# iom480ae register map
Registers are 32-bit, access not given, no defined reset value unless marked. A register's access mark holds for its fields unless they carry their own. Addresses are absolute; registers are grouped by the start of their names; [hi:lo] are bit positions; 'fields as' and 'values as' point back to an identical list.

## CAN
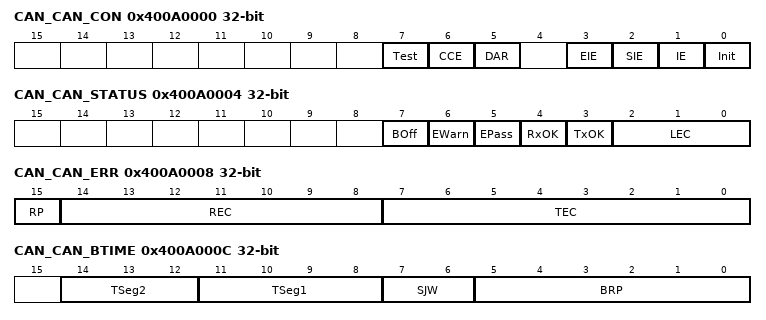
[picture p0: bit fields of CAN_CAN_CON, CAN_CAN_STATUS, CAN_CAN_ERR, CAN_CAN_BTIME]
0x400A0000 CAN_CAN_CON
  [7] Test, [6] CCE, [5] DAR, [3] EIE, [2] SIE, [1] IE, [0] Init
0x400A0004 CAN_CAN_STATUS
  [7] BOff, [6] EWarn, [5] EPass, [4] RxOK, [3] TxOK, [2:0] LEC
0x400A0008 CAN_CAN_ERR
  [15] RP, [14:8] REC, [7:0] TEC
0x400A000C CAN_CAN_BTIME
  [14:12] TSeg2, [11:8] TSeg1, [7:6] SJW, [5:0] BRP
0x400A0010 CAN_CAN_IIDR
  [15:0] IntId
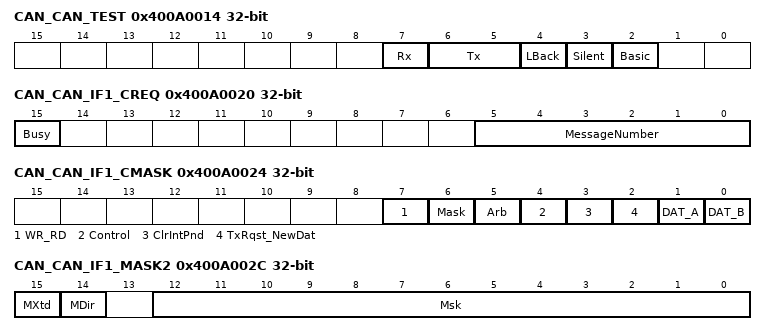
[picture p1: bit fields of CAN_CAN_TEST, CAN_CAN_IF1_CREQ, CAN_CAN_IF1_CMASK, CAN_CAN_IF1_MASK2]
0x400A0014 CAN_CAN_TEST
  [7] Rx, [6:5] Tx, [4] LBack, [3] Silent, [2] Basic
0x400A0018 CAN_CAN_BRPE
  [3:0] BRPE
0x400A0020 CAN_CAN_IF1_CREQ
  [15] Busy, [5:0] MessageNumber
0x400A0024 CAN_CAN_IF1_CMASK
  [7] WR_RD, [6] Mask, [5] Arb, [4] Control, [3] ClrIntPnd, [2] TxRqst_NewDat, [1] DAT_A, [0] DAT_B
0x400A0028 CAN_CAN_IF1_MASK1
  [15:0] Msk
0x400A002C CAN_CAN_IF1_MASK2
  [15] MXtd, [14] MDir, [12:0] Msk
0x400A0030 CAN_CAN_IF1_ARB1
  [15:0] ID
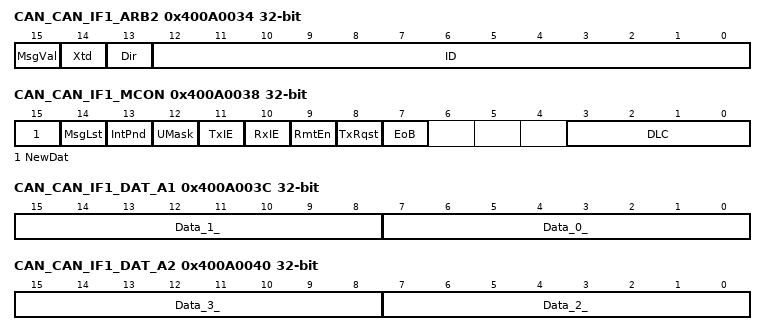
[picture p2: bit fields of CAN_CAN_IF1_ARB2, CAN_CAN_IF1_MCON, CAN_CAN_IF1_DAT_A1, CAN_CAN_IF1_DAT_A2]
0x400A0034 CAN_CAN_IF1_ARB2
  [15] MsgVal, [14] Xtd, [13] Dir, [12:0] ID
0x400A0038 CAN_CAN_IF1_MCON
  [15] NewDat, [14] MsgLst, [13] IntPnd, [12] UMask, [11] TxIE, [10] RxIE, [9] RmtEn, [8] TxRqst, [7] EoB, [3:0] DLC
0x400A003C CAN_CAN_IF1_DAT_A1
  [15:8] Data_1_, [7:0] Data_0_
0x400A0040 CAN_CAN_IF1_DAT_A2
  [15:8] Data_3_, [7:0] Data_2_
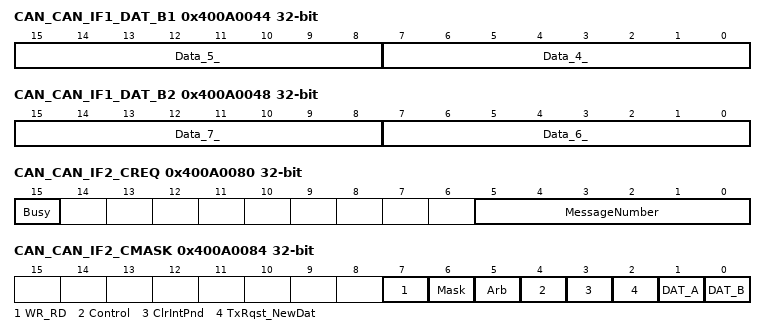
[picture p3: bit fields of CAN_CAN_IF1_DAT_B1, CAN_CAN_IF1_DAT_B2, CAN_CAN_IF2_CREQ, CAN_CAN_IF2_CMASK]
0x400A0044 CAN_CAN_IF1_DAT_B1
  [15:8] Data_5_, [7:0] Data_4_
0x400A0048 CAN_CAN_IF1_DAT_B2
  [15:8] Data_7_, [7:0] Data_6_
0x400A0080 CAN_CAN_IF2_CREQ
  [15] Busy, [5:0] MessageNumber
0x400A0084 CAN_CAN_IF2_CMASK
  fields as CAN_CAN_IF1_CMASK
0x400A0088 CAN_CAN_IF2_MASK1
  [15:0] Msk
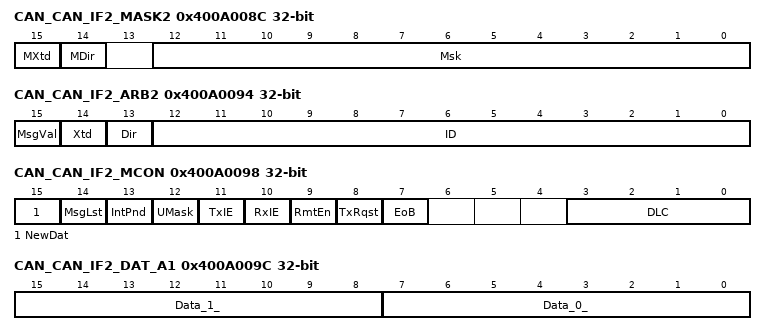
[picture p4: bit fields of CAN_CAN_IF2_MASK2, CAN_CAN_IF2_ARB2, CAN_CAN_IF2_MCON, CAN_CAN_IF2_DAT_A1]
0x400A008C CAN_CAN_IF2_MASK2
  [15] MXtd, [14] MDir, [12:0] Msk
0x400A0090 CAN_CAN_IF2_ARB1
  [15:0] ID
0x400A0094 CAN_CAN_IF2_ARB2
  [15] MsgVal, [14] Xtd, [13] Dir, [12:0] ID
0x400A0098 CAN_CAN_IF2_MCON
  fields as CAN_CAN_IF1_MCON
0x400A009C CAN_CAN_IF2_DAT_A1
  [15:8] Data_1_, [7:0] Data_0_
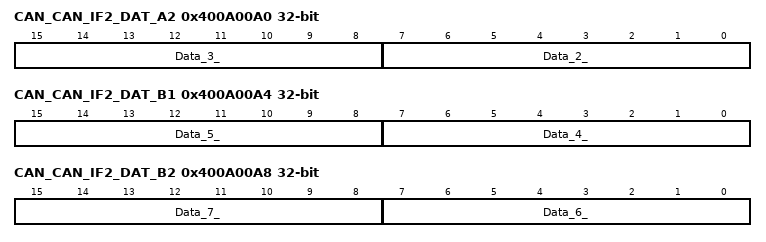
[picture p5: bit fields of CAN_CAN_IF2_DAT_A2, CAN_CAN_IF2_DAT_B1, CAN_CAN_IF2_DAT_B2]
0x400A00A0 CAN_CAN_IF2_DAT_A2
  [15:8] Data_3_, [7:0] Data_2_
0x400A00A4 CAN_CAN_IF2_DAT_B1
  [15:8] Data_5_, [7:0] Data_4_
0x400A00A8 CAN_CAN_IF2_DAT_B2
  [15:8] Data_7_, [7:0] Data_6_
0x400A0100 CAN_CAN_TXREQ1
  [15:0] TxRqst16_1
0x400A0104 CAN_CAN_TXREQ2
  [15:0] TxRqst32_17
0x400A0120 CAN_CAN_NDAT1
  [15:0] NewData16_1
0x400A0124 CAN_CAN_NDAT2
  [15:0] NewData32_17
0x400A0140 CAN_CAN_IPND1
  [15:0] IntPnd16_1
0x400A0144 CAN_CAN_IPND2
  [15:0] IntPnd32_17
0x400A0160 CAN_CAN_MVLD1
  [15:0] MsgVal16_1
0x400A0164 CAN_CAN_MVLD2
  [15:0] MsgVal32_17
0x400A0168 CAN_CAN_WU_EN
  [0] WAKUP_EN
0x400A016C CAN_CAN_WU_STATUS
  [0] WAKUP_STS

## SDH0
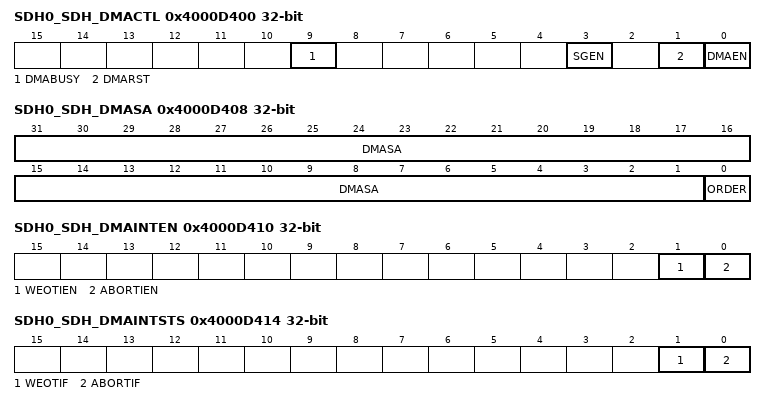
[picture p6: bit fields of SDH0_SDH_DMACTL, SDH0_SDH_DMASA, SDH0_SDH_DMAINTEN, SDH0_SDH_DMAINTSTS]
0x4000D400 SDH0_SDH_DMACTL
  [9] DMABUSY, [3] SGEN, [1] DMARST, [0] DMAEN
0x4000D408 SDH0_SDH_DMASA
  [31:1] DMASA, [0] ORDER
0x4000D40C SDH0_SDH_DMABCNT
  [25:0] BCNT
0x4000D410 SDH0_SDH_DMAINTEN
  [1] WEOTIEN, [0] ABORTIEN
0x4000D414 SDH0_SDH_DMAINTSTS
  [1] WEOTIF, [0] ABORTIF
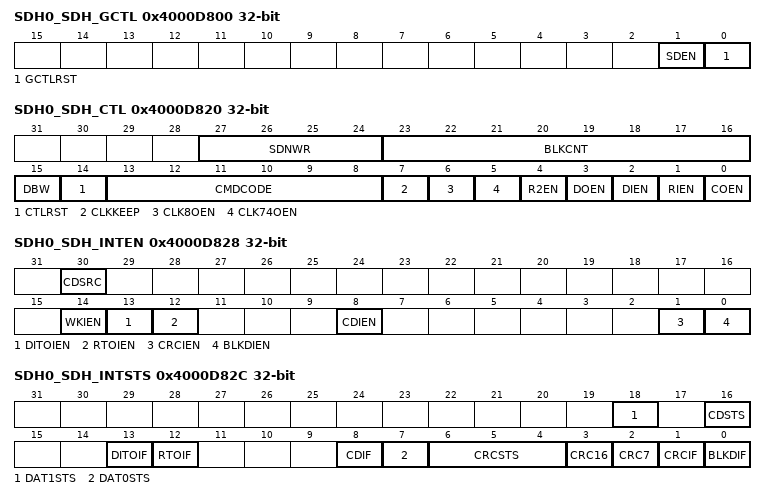
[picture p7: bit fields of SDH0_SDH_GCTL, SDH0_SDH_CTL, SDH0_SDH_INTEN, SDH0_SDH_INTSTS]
0x4000D800 SDH0_SDH_GCTL
  [1] SDEN, [0] GCTLRST
0x4000D804 SDH0_SDH_GINTEN
  [0] DTAIEN
0x4000D808 SDH0_SDH_GINTSTS
  [0] DTAIF
0x4000D820 SDH0_SDH_CTL
  [27:24] SDNWR, [23:16] BLKCNT, [15] DBW, [14] CTLRST, [13:8] CMDCODE, [7] CLKKEEP, [6] CLK8OEN, [5] CLK74OEN, [4] R2EN, [3] DOEN, [2] DIEN, [1] RIEN, [0] COEN
0x4000D824 SDH0_SDH_CMDARG
0x4000D828 SDH0_SDH_INTEN
  [30] CDSRC, [14] WKIEN, [13] DITOIEN, [12] RTOIEN, [8] CDIEN, [1] CRCIEN, [0] BLKDIEN
0x4000D82C SDH0_SDH_INTSTS
  [18] DAT1STS, [16] CDSTS, [13] DITOIF, [12] RTOIF, [8] CDIF, [7] DAT0STS, [6:4] CRCSTS, [3] CRC16, [2] CRC7, [1] CRCIF, [0] BLKDIF
0x4000D830 SDH0_SDH_RESP0
0x4000D834 SDH0_SDH_RESP1
  [7:0] RESPTK1
0x4000D838 SDH0_SDH_BLEN
  [10:0] BLKLEN
0x4000D83C SDH0_SDH_TOUT
  [23:0] TOUT

## SDH1
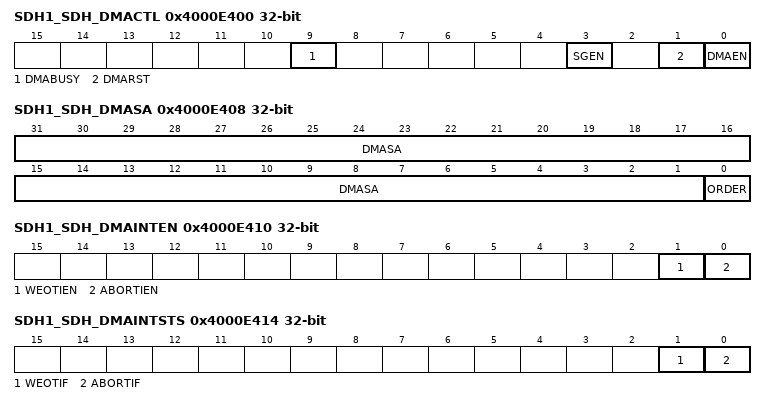
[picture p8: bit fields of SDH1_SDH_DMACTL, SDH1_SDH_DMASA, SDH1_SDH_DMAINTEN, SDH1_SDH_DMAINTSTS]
0x4000E400 SDH1_SDH_DMACTL
  [9] DMABUSY, [3] SGEN, [1] DMARST, [0] DMAEN
0x4000E408 SDH1_SDH_DMASA
  [31:1] DMASA, [0] ORDER
0x4000E40C SDH1_SDH_DMABCNT
  [25:0] BCNT
0x4000E410 SDH1_SDH_DMAINTEN
  [1] WEOTIEN, [0] ABORTIEN
0x4000E414 SDH1_SDH_DMAINTSTS
  [1] WEOTIF, [0] ABORTIF
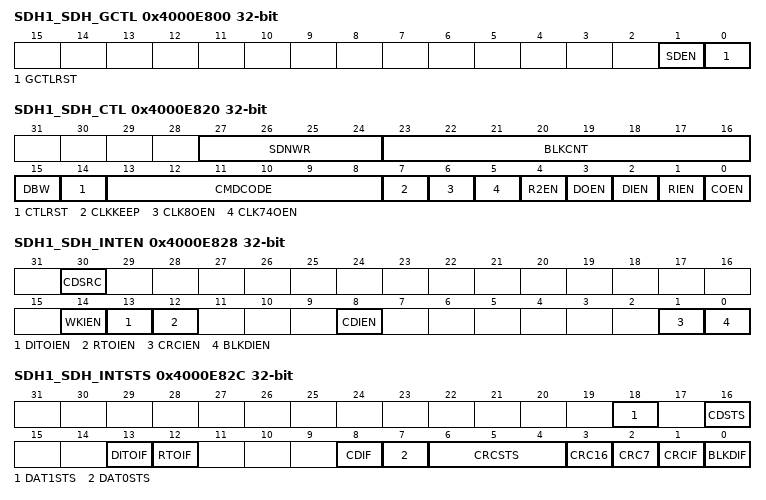
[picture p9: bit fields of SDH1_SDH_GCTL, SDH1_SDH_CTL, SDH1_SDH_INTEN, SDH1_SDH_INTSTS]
0x4000E800 SDH1_SDH_GCTL
  [1] SDEN, [0] GCTLRST
0x4000E804 SDH1_SDH_GINTEN
  [0] DTAIEN
0x4000E808 SDH1_SDH_GINTSTS
  [0] DTAIF
0x4000E820 SDH1_SDH_CTL
  [27:24] SDNWR, [23:16] BLKCNT, [15] DBW, [14] CTLRST, [13:8] CMDCODE, [7] CLKKEEP, [6] CLK8OEN, [5] CLK74OEN, [4] R2EN, [3] DOEN, [2] DIEN, [1] RIEN, [0] COEN
0x4000E824 SDH1_SDH_CMDARG
0x4000E828 SDH1_SDH_INTEN
  [30] CDSRC, [14] WKIEN, [13] DITOIEN, [12] RTOIEN, [8] CDIEN, [1] CRCIEN, [0] BLKDIEN
0x4000E82C SDH1_SDH_INTSTS
  [18] DAT1STS, [16] CDSTS, [13] DITOIF, [12] RTOIF, [8] CDIF, [7] DAT0STS, [6:4] CRCSTS, [3] CRC16, [2] CRC7, [1] CRCIF, [0] BLKDIF
0x4000E830 SDH1_SDH_RESP0
0x4000E834 SDH1_SDH_RESP1
  [7:0] RESPTK1
0x4000E838 SDH1_SDH_BLEN
  [10:0] BLKLEN
0x4000E83C SDH1_SDH_TOUT
  [23:0] TOUT
